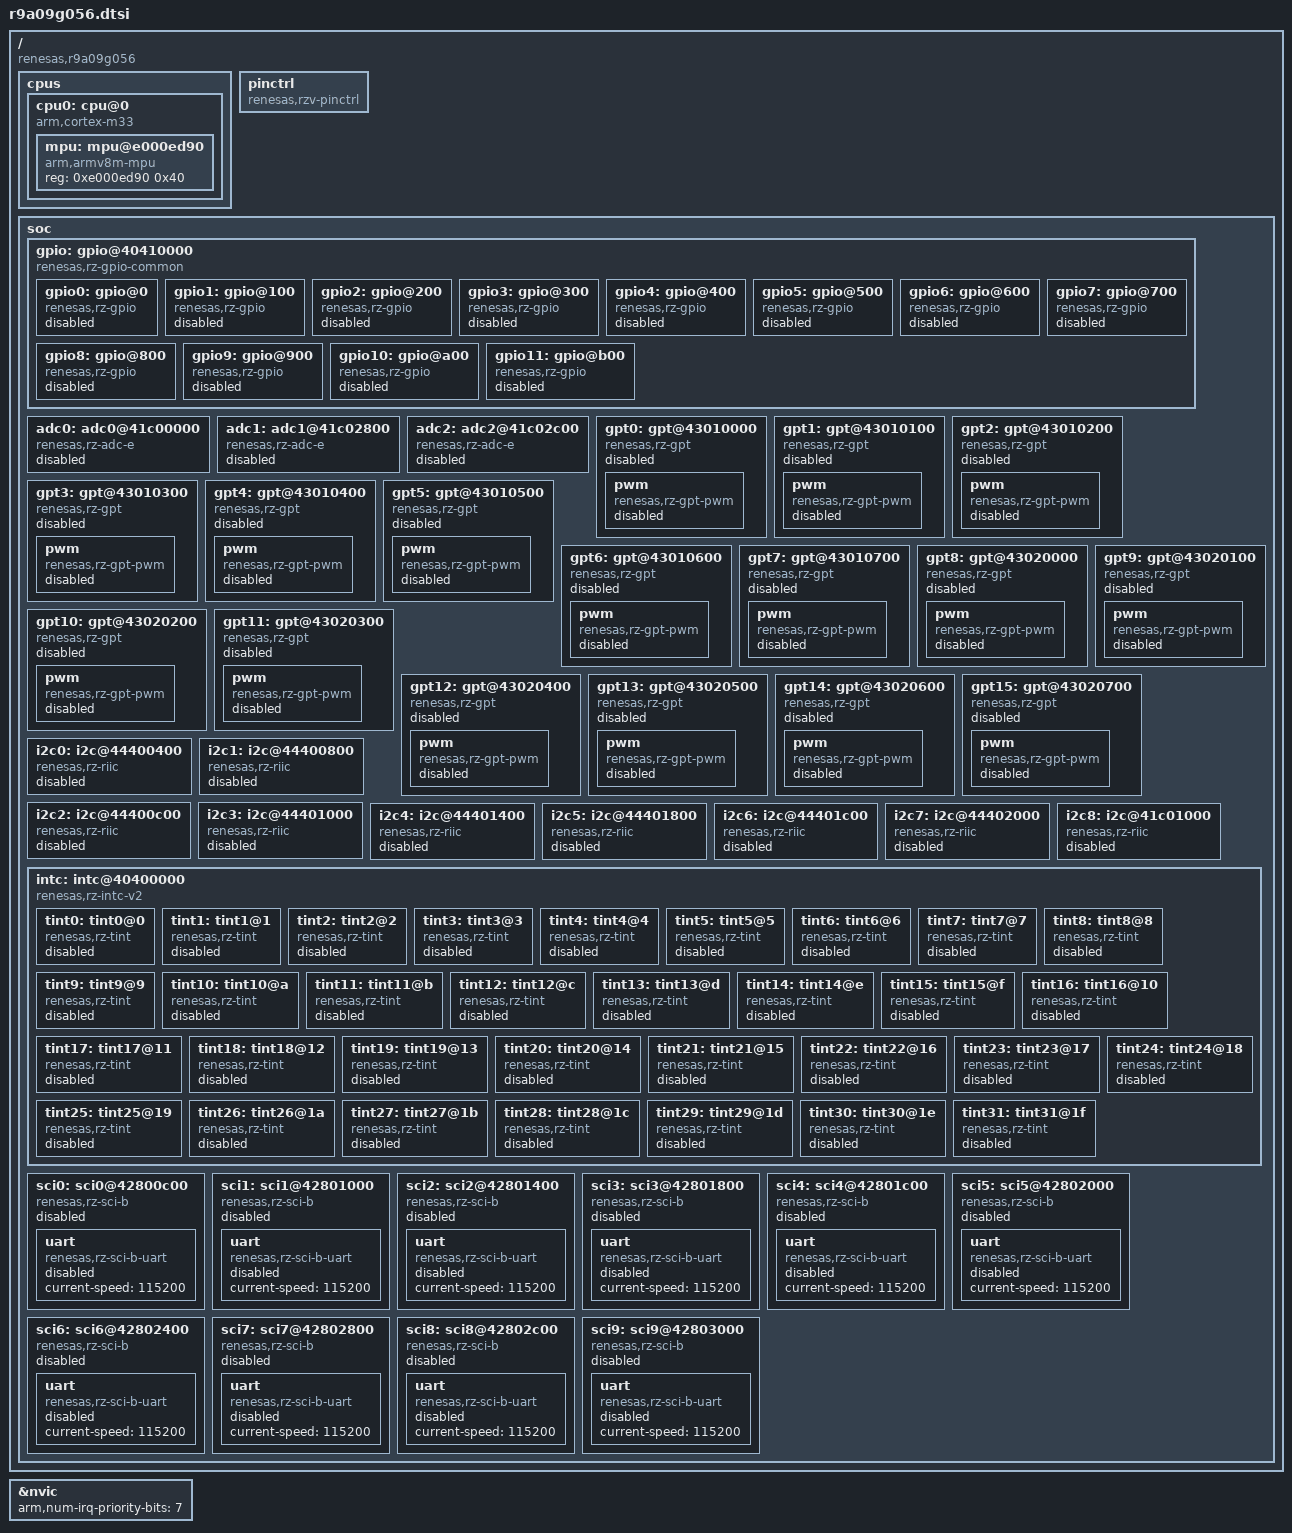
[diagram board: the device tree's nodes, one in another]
/*
 * Copyright (c) 2025 Renesas Electronics Corporation
 * SPDX-License-Identifier: Apache-2.0
 */

#include <arm/armv8-m.dtsi>
#include <mem.h>
#include <freq.h>
#include <zephyr/dt-bindings/adc/adc.h>
#include <zephyr/dt-bindings/gpio/renesas-rz-gpio.h>
#include <zephyr/dt-bindings/i2c/i2c.h>

/ {
	compatible = "renesas,r9a09g056";
	#address-cells = <1>;
	#size-cells = <1>;

	cpus {
		#address-cells = <1>;
		#size-cells = <0>;

		cpu0: cpu@0 {
			device_type = "cpu";
			compatible = "arm,cortex-m33";
			reg = <0>;
			clock-frequency = <DT_FREQ_M(200)>;
			#address-cells = <1>;
			#size-cells = <1>;

			mpu: mpu@e000ed90 {
				compatible = "arm,armv8m-mpu";
				reg = <0xe000ed90 0x40>;
			};
		};
	};

	/* Dummy pinctrl node, filled with pin mux options at board level */
	pinctrl: pinctrl {
		compatible = "renesas,rzv-pinctrl";
	};

	soc {
		gpio: gpio@40410000 {
			compatible = "renesas,rz-gpio-common";
			reg = <0x40410000 DT_SIZE_K(64)>,
			      <0x20 0xc>,
			      <0x140 0x18>,
			      <0x480 0x30>;
			reg-names = "base", "p", "pm", "pfc";
			#address-cells = <1>;
			#size-cells = <0>;

			gpio0: gpio@0 {
				compatible = "renesas,rz-gpio";
				gpio-controller;
				#gpio-cells = <2>;
				ngpios = <8>;
				reg = <0x0>;
				status = "disabled";
			};

			gpio1: gpio@100 {
				compatible = "renesas,rz-gpio";
				gpio-controller;
				#gpio-cells = <2>;
				ngpios = <6>;
				reg = <0x100>;
				status = "disabled";
			};

			gpio2: gpio@200 {
				compatible = "renesas,rz-gpio";
				gpio-controller;
				#gpio-cells = <2>;
				ngpios = <2>;
				reg = <0x200>;
				status = "disabled";
			};

			gpio3: gpio@300 {
				compatible = "renesas,rz-gpio";
				gpio-controller;
				#gpio-cells = <2>;
				ngpios = <8>;
				reg = <0x300>;
				status = "disabled";
			};

			gpio4: gpio@400 {
				compatible = "renesas,rz-gpio";
				gpio-controller;
				#gpio-cells = <2>;
				ngpios = <8>;
				reg = <0x400>;
				status = "disabled";
			};

			gpio5: gpio@500 {
				compatible = "renesas,rz-gpio";
				gpio-controller;
				#gpio-cells = <2>;
				ngpios = <8>;
				reg = <0x500>;
				status = "disabled";
			};

			gpio6: gpio@600 {
				compatible = "renesas,rz-gpio";
				gpio-controller;
				#gpio-cells = <2>;
				ngpios = <8>;
				reg = <0x600>;
				status = "disabled";
			};

			gpio7: gpio@700 {
				compatible = "renesas,rz-gpio";
				gpio-controller;
				#gpio-cells = <2>;
				ngpios = <8>;
				reg = <0x700>;
				status = "disabled";
			};

			gpio8: gpio@800 {
				compatible = "renesas,rz-gpio";
				gpio-controller;
				#gpio-cells = <2>;
				ngpios = <8>;
				reg = <0x800>;
				status = "disabled";
			};

			gpio9: gpio@900 {
				compatible = "renesas,rz-gpio";
				gpio-controller;
				#gpio-cells = <2>;
				ngpios = <8>;
				reg = <0x900>;
				status = "disabled";
			};

			gpio10: gpio@a00 {
				compatible = "renesas,rz-gpio";
				gpio-controller;
				#gpio-cells = <2>;
				ngpios = <8>;
				reg = <0xa00>;
				status = "disabled";
			};

			gpio11: gpio@b00 {
				compatible = "renesas,rz-gpio";
				gpio-controller;
				#gpio-cells = <2>;
				ngpios = <6>;
				reg = <0xb00>;
				status = "disabled";
			};
		};

		adc0: adc0@41c00000 {
			compatible = "renesas,rz-adc-e";
			reg = <0x41c00000 0x400>;
			unit = <0>;
			interrupts = <403 3>;
			interrupt-names = "scanend";
			#io-channel-cells = <1>;
			vref-mv = <1800>;
			channel-available-mask = <0xff>;
			status = "disabled";
		};

		adc1: adc1@41c02800 {
			compatible = "renesas,rz-adc-e";
			reg = <0x41c02800 0x400>;
			unit = <1>;
			interrupts = <404 3>;
			interrupt-names = "scanend";
			#io-channel-cells = <1>;
			vref-mv = <1800>;
			channel-available-mask = <0xff>;
			status = "disabled";
		};

		adc2: adc2@41c02c00 {
			compatible = "renesas,rz-adc-e";
			reg = <0x41c02c00 0x400>;
			unit = <2>;
			interrupts = <405 3>;
			interrupt-names = "scanend";
			#io-channel-cells = <1>;
			vref-mv = <1800>;
			channel-available-mask = <0xff>;
			status = "disabled";
		};

		gpt0: gpt@43010000 {
			compatible = "renesas,rz-gpt";
			reg = <0x43010000 0x100>;
			channel = <0>;
			interrupts = <406 1>, <407 1>, <408 1>;
			interrupt-names = "ccmpa", "ccmpb", "ovf";
			prescaler = <1>;
			status = "disabled";

			pwm {
				compatible = "renesas,rz-gpt-pwm";
				#pwm-cells = <3>;
				status = "disabled";
			};
		};

		gpt1: gpt@43010100 {
			compatible = "renesas,rz-gpt";
			reg = <0x43010100 0x100>;
			channel = <1>;
			interrupts = <409 1>, <410 1>, <411 1>;
			interrupt-names = "ccmpa", "ccmpb", "ovf";
			prescaler = <1>;
			status = "disabled";

			pwm {
				compatible = "renesas,rz-gpt-pwm";
				#pwm-cells = <3>;
				status = "disabled";
			};
		};

		gpt2: gpt@43010200 {
			compatible = "renesas,rz-gpt";
			reg = <0x43010200 0x100>;
			channel = <2>;
			interrupts = <412 1>, <413 1>, <414 1>;
			interrupt-names = "ccmpa", "ccmpb", "ovf";
			prescaler = <1>;
			status = "disabled";

			pwm {
				compatible = "renesas,rz-gpt-pwm";
				#pwm-cells = <3>;
				status = "disabled";
			};
		};

		gpt3: gpt@43010300 {
			compatible = "renesas,rz-gpt";
			reg = <0x43010300 0x100>;
			channel = <3>;
			interrupts = <415 1>, <416 1>, <417 1>;
			interrupt-names = "ccmpa", "ccmpb", "ovf";
			prescaler = <1>;
			status = "disabled";

			pwm {
				compatible = "renesas,rz-gpt-pwm";
				#pwm-cells = <3>;
				status = "disabled";
			};
		};

		gpt4: gpt@43010400 {
			compatible = "renesas,rz-gpt";
			reg = <0x43010400 0x100>;
			channel = <4>;
			interrupts = <418 1>, <419 1>, <420 1>;
			interrupt-names = "ccmpa", "ccmpb", "ovf";
			prescaler = <1>;
			status = "disabled";

			pwm {
				compatible = "renesas,rz-gpt-pwm";
				#pwm-cells = <3>;
				status = "disabled";
			};
		};

		gpt5: gpt@43010500 {
			compatible = "renesas,rz-gpt";
			reg = <0x43010500 0x100>;
			channel = <5>;
			interrupts = <421 1>, <422 1>, <423 1>;
			interrupt-names = "ccmpa", "ccmpb", "ovf";
			prescaler = <1>;
			status = "disabled";

			pwm {
				compatible = "renesas,rz-gpt-pwm";
				#pwm-cells = <3>;
				status = "disabled";
			};
		};

		gpt6: gpt@43010600 {
			compatible = "renesas,rz-gpt";
			reg = <0x43010600 0x100>;
			channel = <6>;
			interrupts = <424 1>, <425 1>, <426 1>;
			interrupt-names = "ccmpa", "ccmpb", "ovf";
			prescaler = <1>;
			status = "disabled";

			pwm {
				compatible = "renesas,rz-gpt-pwm";
				#pwm-cells = <3>;
				status = "disabled";
			};
		};

		gpt7: gpt@43010700 {
			compatible = "renesas,rz-gpt";
			reg = <0x43010700 0x100>;
			channel = <7>;
			interrupts = <427 1>, <428 1>, <429 1>;
			interrupt-names = "ccmpa", "ccmpb", "ovf";
			prescaler = <1>;
			status = "disabled";

			pwm {
				compatible = "renesas,rz-gpt-pwm";
				#pwm-cells = <3>;
				status = "disabled";
			};
		};

		gpt8: gpt@43020000 {
			compatible = "renesas,rz-gpt";
			reg = <0x43020000 0x100>;
			channel = <8>;
			interrupts = <430 1>, <431 1>, <432 1>;
			interrupt-names = "ccmpa", "ccmpb", "ovf";
			prescaler = <1>;
			status = "disabled";

			pwm {
				compatible = "renesas,rz-gpt-pwm";
				#pwm-cells = <3>;
				status = "disabled";
			};
		};

		gpt9: gpt@43020100 {
			compatible = "renesas,rz-gpt";
			reg = <0x43020100 0x100>;
			channel = <9>;
			interrupts = <433 1>, <434 1>, <435 1>;
			interrupt-names = "ccmpa", "ccmpb", "ovf";
			prescaler = <1>;
			status = "disabled";

			pwm {
				compatible = "renesas,rz-gpt-pwm";
				#pwm-cells = <3>;
				status = "disabled";
			};
		};

		gpt10: gpt@43020200 {
			compatible = "renesas,rz-gpt";
			reg = <0x43020200 0x100>;
			channel = <10>;
			interrupts = <436 1>, <437 1>, <438 1>;
			interrupt-names = "ccmpa", "ccmpb", "ovf";
			prescaler = <1>;
			status = "disabled";

			pwm {
				compatible = "renesas,rz-gpt-pwm";
				#pwm-cells = <3>;
				status = "disabled";
			};
		};

		gpt11: gpt@43020300 {
			compatible = "renesas,rz-gpt";
			reg = <0x43020300 0x100>;
			channel = <11>;
			interrupts = <439 1>, <440 1>, <441 1>;
			interrupt-names = "ccmpa", "ccmpb", "ovf";
			prescaler = <1>;
			status = "disabled";

			pwm {
				compatible = "renesas,rz-gpt-pwm";
				#pwm-cells = <3>;
				status = "disabled";
			};
		};

		gpt12: gpt@43020400 {
			compatible = "renesas,rz-gpt";
			reg = <0x43020400 0x100>;
			channel = <12>;
			interrupts = <442 1>, <443 1>, <444 1>;
			interrupt-names = "ccmpa", "ccmpb", "ovf";
			prescaler = <1>;
			status = "disabled";

			pwm {
				compatible = "renesas,rz-gpt-pwm";
				#pwm-cells = <3>;
				status = "disabled";
			};
		};

		gpt13: gpt@43020500 {
			compatible = "renesas,rz-gpt";
			reg = <0x43020500 0x100>;
			channel = <13>;
			interrupts = <445 1>, <446 1>, <447 1>;
			interrupt-names = "ccmpa", "ccmpb", "ovf";
			prescaler = <1>;
			status = "disabled";

			pwm {
				compatible = "renesas,rz-gpt-pwm";
				#pwm-cells = <3>;
				status = "disabled";
			};
		};

		gpt14: gpt@43020600 {
			compatible = "renesas,rz-gpt";
			reg = <0x43020600 0x100>;
			channel = <14>;
			interrupts = <448 1>, <449 1>, <450 1>;
			interrupt-names = "ccmpa", "ccmpb", "ovf";
			prescaler = <1>;
			status = "disabled";

			pwm {
				compatible = "renesas,rz-gpt-pwm";
				#pwm-cells = <3>;
				status = "disabled";
			};
		};

		gpt15: gpt@43020700 {
			compatible = "renesas,rz-gpt";
			reg = <0x43020700 0x100>;
			channel = <15>;
			interrupts = <451 1>, <452 1>, <453 1>;
			interrupt-names = "ccmpa", "ccmpb", "ovf";
			prescaler = <1>;
			status = "disabled";

			pwm {
				compatible = "renesas,rz-gpt-pwm";
				#pwm-cells = <3>;
				status = "disabled";
			};
		};

		i2c0: i2c@44400400 {
			compatible = "renesas,rz-riic";
			channel = <0>;
			clock-frequency = <I2C_BITRATE_STANDARD>;
			#address-cells = <1>;
			#size-cells = <0>;
			reg = <0x44400400 DT_SIZE_K(1)>;
			interrupts = <174 1>, <175 1>, <176 1>, <177 1>,
				     <178 1>, <179 1>, <385 1>, <386 1>;
			interrupt-names = "tei", "naki", "spi", "sti", "ali", "tmoi", "txi", "rxi";
			status = "disabled";
		};

		i2c1: i2c@44400800 {
			compatible = "renesas,rz-riic";
			channel = <1>;
			clock-frequency = <I2C_BITRATE_STANDARD>;
			#address-cells = <1>;
			#size-cells = <0>;
			reg = <0x44400800 DT_SIZE_K(1)>;
			interrupts = <180 1>, <181 1>, <182 1>, <183 1>,
				     <184 1>, <185 1>, <387 1>, <388 1>;
			interrupt-names = "tei", "naki", "spi", "sti", "ali", "tmoi", "txi", "rxi";
			status = "disabled";
		};

		i2c2: i2c@44400c00 {
			compatible = "renesas,rz-riic";
			channel = <2>;
			clock-frequency = <I2C_BITRATE_STANDARD>;
			#address-cells = <1>;
			#size-cells = <0>;
			reg = <0x44400c00 DT_SIZE_K(1)>;
			interrupts = <186 1>, <187 1>, <188 1>, <189 1>,
				     <190 1>, <191 1>, <389 1>, <390 1>;
			interrupt-names = "tei", "naki", "spi", "sti", "ali", "tmoi", "txi", "rxi";
			status = "disabled";
		};

		i2c3: i2c@44401000 {
			compatible = "renesas,rz-riic";
			channel = <3>;
			clock-frequency = <I2C_BITRATE_STANDARD>;
			#address-cells = <1>;
			#size-cells = <0>;
			reg = <0x44401000 DT_SIZE_K(1)>;
			interrupts = <192 1>, <193 1>, <194 1>, <195 1>,
				     <196 1>, <197 1>, <391 1>, <392 1>;
			interrupt-names = "tei", "naki", "spi", "sti", "ali", "tmoi", "txi", "rxi";
			status = "disabled";
		};

		i2c4: i2c@44401400 {
			compatible = "renesas,rz-riic";
			channel = <4>;
			clock-frequency = <I2C_BITRATE_STANDARD>;
			#address-cells = <1>;
			#size-cells = <0>;
			reg = <0x44401400 DT_SIZE_K(1)>;
			interrupts = <198 1>, <199 1>, <200 1>, <201 1>,
				     <202 1>, <203 1>, <393 1>, <394 1>;
			interrupt-names = "tei", "naki", "spi", "sti", "ali", "tmoi", "txi", "rxi";
			status = "disabled";
		};

		i2c5: i2c@44401800 {
			compatible = "renesas,rz-riic";
			channel = <5>;
			clock-frequency = <I2C_BITRATE_STANDARD>;
			#address-cells = <1>;
			#size-cells = <0>;
			reg = <0x44401800 DT_SIZE_K(1)>;
			interrupts = <204 1>, <205 1>, <206 1>, <207 1>,
				     <208 1>, <209 1>, <395 1>, <396 1>;
			interrupt-names = "tei", "naki", "spi", "sti", "ali", "tmoi", "txi", "rxi";
			status = "disabled";
		};

		i2c6: i2c@44401c00 {
			compatible = "renesas,rz-riic";
			channel = <6>;
			clock-frequency = <I2C_BITRATE_STANDARD>;
			#address-cells = <1>;
			#size-cells = <0>;
			reg = <0x44401c00 DT_SIZE_K(1)>;
			interrupts = <210 1>, <211 1>, <212 1>, <213 1>,
				     <214 1>, <215 1>, <397 1>, <398 1>;
			interrupt-names = "tei", "naki", "spi", "sti", "ali", "tmoi", "txi", "rxi";
			status = "disabled";
		};

		i2c7: i2c@44402000 {
			compatible = "renesas,rz-riic";
			channel = <7>;
			clock-frequency = <I2C_BITRATE_STANDARD>;
			#address-cells = <1>;
			#size-cells = <0>;
			reg = <0x44402000 DT_SIZE_K(1)>;
			interrupts = <216 1>, <217 1>, <218 1>, <219 1>,
				     <220 1>, <221 1>, <399 1>, <400 1>;
			interrupt-names = "tei", "naki", "spi", "sti", "ali", "tmoi", "txi", "rxi";
			status = "disabled";
		};

		i2c8: i2c@41c01000 {
			compatible = "renesas,rz-riic";
			channel = <8>;
			clock-frequency = <I2C_BITRATE_STANDARD>;
			#address-cells = <1>;
			#size-cells = <0>;
			reg = <0x41c01000 DT_SIZE_K(1)>;
			interrupts = <222 1>, <223 1>, <224 1>, <225 1>,
				     <226 1>, <227 1>, <401 1>, <402 1>;
			interrupt-names = "tei", "naki", "spi", "sti", "ali", "tmoi", "txi", "rxi";
			status = "disabled";
		};

		intc: intc@40400000 {
			compatible = "renesas,rz-intc-v2";
			reg = <0x40400000 DT_SIZE_K(64)>,
			      <0x20 0x4>,
			      <0x28 0x4>,
			      <0x30 0x4>,
			      <0x200 0xac>;
			reg-names = "intc", "tscr", "titsr0", "tssr0", "intsel";
			gpioint-table = <0 8 14 16 24 32 40 48 56 64 72 80>;
			max-gpioint = <85>;
			#address-cells = <1>;
			#size-cells = <0>;
			interrupt-parent = <&nvic>;

			tint0: tint0@0 {
				compatible = "renesas,rz-tint";
				reg = <0x0>;
				interrupts = <353 1>;
				trigger-type = "rising";
				#irq-cells = <1>;
				status = "disabled";
			};

			tint1: tint1@1 {
				compatible = "renesas,rz-tint";
				reg = <0x1>;
				interrupts = <354 1>;
				trigger-type = "rising";
				#irq-cells = <1>;
				status = "disabled";
			};

			tint2: tint2@2 {
				compatible = "renesas,rz-tint";
				reg = <0x2>;
				interrupts = <355 1>;
				trigger-type = "rising";
				#irq-cells = <1>;
				status = "disabled";
			};

			tint3: tint3@3 {
				compatible = "renesas,rz-tint";
				reg = <0x3>;
				interrupts = <356 1>;
				trigger-type = "rising";
				#irq-cells = <1>;
				status = "disabled";
			};

			tint4: tint4@4 {
				compatible = "renesas,rz-tint";
				reg = <0x4>;
				interrupts = <357 1>;
				trigger-type = "rising";
				#irq-cells = <1>;
				status = "disabled";
			};

			tint5: tint5@5 {
				compatible = "renesas,rz-tint";
				reg = <0x5>;
				interrupts = <358 1>;
				trigger-type = "rising";
				#irq-cells = <1>;
				status = "disabled";
			};

			tint6: tint6@6 {
				compatible = "renesas,rz-tint";
				reg = <0x6>;
				interrupts = <359 1>;
				trigger-type = "rising";
				#irq-cells = <1>;
				status = "disabled";
			};

			tint7: tint7@7 {
				compatible = "renesas,rz-tint";
				reg = <0x7>;
				interrupts = <360 1>;
				trigger-type = "rising";
				#irq-cells = <1>;
				status = "disabled";
			};

			tint8: tint8@8 {
				compatible = "renesas,rz-tint";
				reg = <0x8>;
				interrupts = <361 1>;
				trigger-type = "rising";
				#irq-cells = <1>;
				status = "disabled";
			};

			tint9: tint9@9 {
				compatible = "renesas,rz-tint";
				reg = <0x9>;
				interrupts = <362 1>;
				trigger-type = "rising";
				#irq-cells = <1>;
				status = "disabled";
			};

			tint10: tint10@a {
				compatible = "renesas,rz-tint";
				reg = <0xa>;
				interrupts = <363 1>;
				trigger-type = "rising";
				#irq-cells = <1>;
				status = "disabled";
			};

			tint11: tint11@b {
				compatible = "renesas,rz-tint";
				reg = <0xb>;
				interrupts = <364 1>;
				trigger-type = "rising";
				#irq-cells = <1>;
				status = "disabled";
			};

			tint12: tint12@c {
				compatible = "renesas,rz-tint";
				reg = <0xc>;
				interrupts = <365 1>;
				trigger-type = "rising";
				#irq-cells = <1>;
				status = "disabled";
			};

			tint13: tint13@d {
				compatible = "renesas,rz-tint";
				reg = <0xd>;
				interrupts = <366 1>;
				trigger-type = "rising";
				#irq-cells = <1>;
				status = "disabled";
			};

			tint14: tint14@e {
				compatible = "renesas,rz-tint";
				reg = <0xe>;
				interrupts = <367 1>;
				trigger-type = "rising";
				#irq-cells = <1>;
				status = "disabled";
			};

			tint15: tint15@f {
				compatible = "renesas,rz-tint";
				reg = <0xf>;
				interrupts = <368 1>;
				trigger-type = "rising";
				#irq-cells = <1>;
				status = "disabled";
			};

			tint16: tint16@10 {
				compatible = "renesas,rz-tint";
				reg = <0x10>;
				interrupts = <369 1>;
				trigger-type = "rising";
				#irq-cells = <1>;
				status = "disabled";
			};

			tint17: tint17@11 {
				compatible = "renesas,rz-tint";
				reg = <0x11>;
				interrupts = <370 1>;
				trigger-type = "rising";
				#irq-cells = <1>;
				status = "disabled";
			};

			tint18: tint18@12 {
				compatible = "renesas,rz-tint";
				reg = <0x12>;
				interrupts = <371 1>;
				trigger-type = "rising";
				#irq-cells = <1>;
				status = "disabled";
			};

			tint19: tint19@13 {
				compatible = "renesas,rz-tint";
				reg = <0x13>;
				interrupts = <372 1>;
				trigger-type = "rising";
				#irq-cells = <1>;
				status = "disabled";
			};

			tint20: tint20@14 {
				compatible = "renesas,rz-tint";
				reg = <0x14>;
				interrupts = <373 1>;
				trigger-type = "rising";
				#irq-cells = <1>;
				status = "disabled";
			};

			tint21: tint21@15 {
				compatible = "renesas,rz-tint";
				reg = <0x15>;
				interrupts = <374 1>;
				trigger-type = "rising";
				#irq-cells = <1>;
				status = "disabled";
			};

			tint22: tint22@16 {
				compatible = "renesas,rz-tint";
				reg = <0x16>;
				interrupts = <375 1>;
				trigger-type = "rising";
				#irq-cells = <1>;
				status = "disabled";
			};

			tint23: tint23@17 {
				compatible = "renesas,rz-tint";
				reg = <0x17>;
				interrupts = <376 1>;
				trigger-type = "rising";
				#irq-cells = <1>;
				status = "disabled";
			};

			tint24: tint24@18 {
				compatible = "renesas,rz-tint";
				reg = <0x18>;
				interrupts = <377 1>;
				trigger-type = "rising";
				#irq-cells = <1>;
				status = "disabled";
			};

			tint25: tint25@19 {
				compatible = "renesas,rz-tint";
				reg = <0x19>;
				interrupts = <378 1>;
				trigger-type = "rising";
				#irq-cells = <1>;
				status = "disabled";
			};

			tint26: tint26@1a {
				compatible = "renesas,rz-tint";
				reg = <0x1a>;
				interrupts = <379 1>;
				trigger-type = "rising";
				#irq-cells = <1>;
				status = "disabled";
			};

			tint27: tint27@1b {
				compatible = "renesas,rz-tint";
				reg = <0x1b>;
				interrupts = <380 1>;
				trigger-type = "rising";
				#irq-cells = <1>;
				status = "disabled";
			};

			tint28: tint28@1c {
				compatible = "renesas,rz-tint";
				reg = <0x1c>;
				interrupts = <381 1>;
				trigger-type = "rising";
				#irq-cells = <1>;
				status = "disabled";
			};

			tint29: tint29@1d {
				compatible = "renesas,rz-tint";
				reg = <0x1d>;
				interrupts = <382 1>;
				trigger-type = "rising";
				#irq-cells = <1>;
				status = "disabled";
			};

			tint30: tint30@1e {
				compatible = "renesas,rz-tint";
				reg = <0x1e>;
				interrupts = <383 1>;
				trigger-type = "rising";
				#irq-cells = <1>;
				status = "disabled";
			};

			tint31: tint31@1f {
				compatible = "renesas,rz-tint";
				reg = <0x1f>;
				interrupts = <384 1>;
				trigger-type = "rising";
				#irq-cells = <1>;
				status = "disabled";
			};
		};

		sci0: sci0@42800c00 {
			compatible = "renesas,rz-sci-b";
			reg = <0x42800c00 0x400>;
			channel = <0>;
			interrupts = <114 1>, <115 1>, <116 1>, <117 1>;
			interrupt-names = "eri", "rxi", "txi", "tei";
			status = "disabled";

			uart {
				compatible = "renesas,rz-sci-b-uart";
				current-speed = <115200>;
				status = "disabled";
			};
		};

		sci1: sci1@42801000 {
			compatible = "renesas,rz-sci-b";
			reg = <0x42801000 0x400>;
			channel = <1>;
			interrupts = <120 1>, <121 1>, <122 1>, <123 1>;
			interrupt-names = "eri", "rxi", "txi", "tei";
			status = "disabled";

			uart {
				compatible = "renesas,rz-sci-b-uart";
				current-speed = <115200>;
				status = "disabled";
			};
		};

		sci2: sci2@42801400 {
			compatible = "renesas,rz-sci-b";
			reg = <0x42801400 0x400>;
			channel = <2>;
			interrupts = <126 1>, <127 1>, <128 1>, <129 1>;
			interrupt-names = "eri", "rxi", "txi", "tei";
			status = "disabled";

			uart {
				compatible = "renesas,rz-sci-b-uart";
				current-speed = <115200>;
				status = "disabled";
			};
		};

		sci3: sci3@42801800 {
			compatible = "renesas,rz-sci-b";
			reg = <0x42801800 0x400>;
			channel = <3>;
			interrupts = <132 1>, <133 1>, <134 1>, <135 1>;
			interrupt-names = "eri", "rxi", "txi", "tei";
			status = "disabled";

			uart {
				compatible = "renesas,rz-sci-b-uart";
				current-speed = <115200>;
				status = "disabled";
			};
		};

		sci4: sci4@42801c00 {
			compatible = "renesas,rz-sci-b";
			reg = <0x42801c00 0x400>;
			channel = <4>;
			interrupts = <138 1>, <139 1>, <140 1>, <141 1>;
			interrupt-names = "eri", "rxi", "txi", "tei";
			status = "disabled";

			uart {
				compatible = "renesas,rz-sci-b-uart";
				current-speed = <115200>;
				status = "disabled";
			};
		};

		sci5: sci5@42802000 {
			compatible = "renesas,rz-sci-b";
			reg = <0x42802000 0x400>;
			channel = <5>;
			interrupts = <144 1>, <145 1>, <146 1>, <147 1>;
			interrupt-names = "eri", "rxi", "txi", "tei";
			status = "disabled";

			uart {
				compatible = "renesas,rz-sci-b-uart";
				current-speed = <115200>;
				status = "disabled";
			};
		};

		sci6: sci6@42802400 {
			compatible = "renesas,rz-sci-b";
			reg = <0x42802400 0x400>;
			channel = <6>;
			interrupts = <150 1>, <151 1>, <152 1>, <153 1>;
			interrupt-names = "eri", "rxi", "txi", "tei";
			status = "disabled";

			uart {
				compatible = "renesas,rz-sci-b-uart";
				current-speed = <115200>;
				status = "disabled";
			};
		};

		sci7: sci7@42802800 {
			compatible = "renesas,rz-sci-b";
			reg = <0x42802800 0x400>;
			channel = <7>;
			interrupts = <156 1>, <157 1>, <158 1>, <159 1>;
			interrupt-names = "eri", "rxi", "txi", "tei";
			status = "disabled";

			uart {
				compatible = "renesas,rz-sci-b-uart";
				current-speed = <115200>;
				status = "disabled";
			};
		};

		sci8: sci8@42802c00 {
			compatible = "renesas,rz-sci-b";
			reg = <0x42802c00 0x400>;
			channel = <8>;
			interrupts = <162 1>, <163 1>, <164 1>, <165 1>;
			interrupt-names = "eri", "rxi", "txi", "tei";
			status = "disabled";

			uart {
				compatible = "renesas,rz-sci-b-uart";
				current-speed = <115200>;
				status = "disabled";
			};
		};

		sci9: sci9@42803000 {
			compatible = "renesas,rz-sci-b";
			reg = <0x42803000 0x400>;
			channel = <9>;
			interrupts = <168 1>, <169 1>, <170 1>, <171 1>;
			interrupt-names = "eri", "rxi", "txi", "tei";
			status = "disabled";

			uart {
				compatible = "renesas,rz-sci-b-uart";
				current-speed = <115200>;
				status = "disabled";
			};
		};
	};
};

&nvic {
	arm,num-irq-priority-bits = <7>;
};
